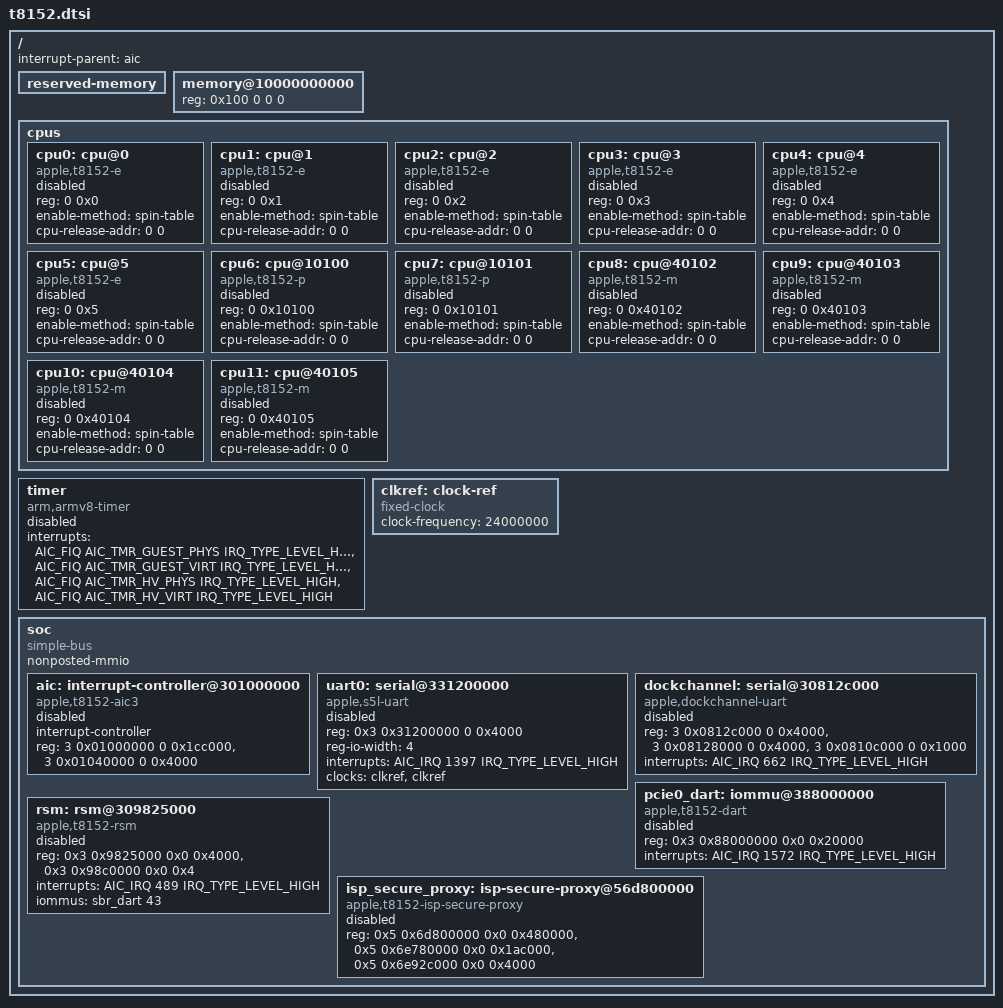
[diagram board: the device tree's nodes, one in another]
// SPDX-License-Identifier: GPL-2.0+ OR MIT
/*
 * Common hardware inventory for boards without a qualified boot profile.
 * Firmware fills RAM and CPU release addresses. Keep new devices disabled;
 * CPU harvesting, firmware handoff and enables need separate qualification.
 */
#include <dt-bindings/interrupt-controller/apple-aic.h>
#include <dt-bindings/interrupt-controller/irq.h>

/ {
	#address-cells = <2>;
	#size-cells = <2>;
	interrupt-parent = <&aic>;

	reserved-memory {
		#address-cells = <2>;
		#size-cells = <2>;
		ranges;
	};

	memory@10000000000 {
		device_type = "memory";
		reg = <0x100 0 0 0>; /* Filled by the loader. */
	};

	cpus {
		#address-cells = <2>;
		#size-cells = <0>;

		cpu0: cpu@0 {
			status = "disabled";
			compatible = "apple,t8152-e";
			device_type = "cpu";
			reg = <0 0x0>;
			enable-method = "spin-table";
			cpu-release-addr = <0 0>; /* Filled by the loader. */
		};

		cpu1: cpu@1 {
			status = "disabled";
			compatible = "apple,t8152-e";
			device_type = "cpu";
			reg = <0 0x1>;
			enable-method = "spin-table";
			cpu-release-addr = <0 0>; /* Filled by the loader. */
		};

		cpu2: cpu@2 {
			status = "disabled";
			compatible = "apple,t8152-e";
			device_type = "cpu";
			reg = <0 0x2>;
			enable-method = "spin-table";
			cpu-release-addr = <0 0>; /* Filled by the loader. */
		};

		cpu3: cpu@3 {
			status = "disabled";
			compatible = "apple,t8152-e";
			device_type = "cpu";
			reg = <0 0x3>;
			enable-method = "spin-table";
			cpu-release-addr = <0 0>; /* Filled by the loader. */
		};

		cpu4: cpu@4 {
			status = "disabled";
			compatible = "apple,t8152-e";
			device_type = "cpu";
			reg = <0 0x4>;
			enable-method = "spin-table";
			cpu-release-addr = <0 0>; /* Filled by the loader. */
		};

		cpu5: cpu@5 {
			status = "disabled";
			compatible = "apple,t8152-e";
			device_type = "cpu";
			reg = <0 0x5>;
			enable-method = "spin-table";
			cpu-release-addr = <0 0>; /* Filled by the loader. */
		};

		cpu6: cpu@10100 {
			status = "disabled";
			compatible = "apple,t8152-p";
			device_type = "cpu";
			reg = <0 0x10100>;
			enable-method = "spin-table";
			cpu-release-addr = <0 0>; /* Filled by the loader. */
		};

		cpu7: cpu@10101 {
			status = "disabled";
			compatible = "apple,t8152-p";
			device_type = "cpu";
			reg = <0 0x10101>;
			enable-method = "spin-table";
			cpu-release-addr = <0 0>; /* Filled by the loader. */
		};

		cpu8: cpu@40102 {
			status = "disabled";
			compatible = "apple,t8152-m";
			device_type = "cpu";
			reg = <0 0x40102>;
			enable-method = "spin-table";
			cpu-release-addr = <0 0>; /* Filled by the loader. */
		};

		cpu9: cpu@40103 {
			status = "disabled";
			compatible = "apple,t8152-m";
			device_type = "cpu";
			reg = <0 0x40103>;
			enable-method = "spin-table";
			cpu-release-addr = <0 0>; /* Filled by the loader. */
		};

		cpu10: cpu@40104 {
			status = "disabled";
			compatible = "apple,t8152-m";
			device_type = "cpu";
			reg = <0 0x40104>;
			enable-method = "spin-table";
			cpu-release-addr = <0 0>; /* Filled by the loader. */
		};

		cpu11: cpu@40105 {
			status = "disabled";
			compatible = "apple,t8152-m";
			device_type = "cpu";
			reg = <0 0x40105>;
			enable-method = "spin-table";
			cpu-release-addr = <0 0>; /* Filled by the loader. */
		};
	};

	timer {
		status = "disabled";
		compatible = "arm,armv8-timer";
		interrupts = <AIC_FIQ AIC_TMR_GUEST_PHYS IRQ_TYPE_LEVEL_HIGH>,
			     <AIC_FIQ AIC_TMR_GUEST_VIRT IRQ_TYPE_LEVEL_HIGH>,
			     <AIC_FIQ AIC_TMR_HV_PHYS IRQ_TYPE_LEVEL_HIGH>,
			     <AIC_FIQ AIC_TMR_HV_VIRT IRQ_TYPE_LEVEL_HIGH>;
		interrupt-names = "phys", "virt", "hyp-phys", "hyp-virt";
	};

	clkref: clock-ref {
		compatible = "fixed-clock";
		#clock-cells = <0>;
		clock-frequency = <24000000>;
	};

	soc {
		compatible = "simple-bus";
		#address-cells = <2>;
		#size-cells = <2>;
		ranges;
		nonposted-mmio;

		aic: interrupt-controller@301000000 {
			status = "disabled";
			compatible = "apple,t8152-aic3", "apple,t8122-aic3";
			interrupt-controller;
			#interrupt-cells = <3>;
			reg = <3 0x01000000 0 0x1cc000>,
			      <3 0x01040000 0 0x4000>;
			reg-names = "core", "event";
		};

	uart0: serial@331200000 {
		status = "disabled";
		compatible = "apple,s5l-uart";
		reg = <0x3 0x31200000 0 0x4000>;
		reg-io-width = <4>;
		interrupts = <AIC_IRQ 1397 IRQ_TYPE_LEVEL_HIGH>;
		clocks = <&clkref>, <&clkref>;
		clock-names = "uart", "clk_uart_baud0";
	};

		dockchannel: serial@30812c000 {
			status = "disabled";
			compatible = "apple,dockchannel-uart";
			reg = <3 0x0812c000 0 0x4000>,
			      <3 0x08128000 0 0x4000>,
			      <3 0x0810c000 0 0x1000>;
			reg-names = "data", "config", "irq";
			interrupts = <AIC_IRQ 662 IRQ_TYPE_LEVEL_HIGH>;
		};
	};
};

/* Native interfaces shared by the hardware-only board descriptions. */
&{/soc} {
	pcie0_dart: iommu@388000000 {
		compatible = "apple,t8152-dart", "apple,t8110-dart";
		reg = <0x3 0x88000000 0x0 0x20000>;
		interrupts = <AIC_IRQ 1572 IRQ_TYPE_LEVEL_HIGH>;
		#iommu-cells = <1>;
		status = "disabled";
	};

	rsm: rsm@309825000 {
		compatible = "apple,t8152-rsm", "apple,rsm";
		reg = <0x3 0x9825000 0x0 0x4000>,
		      <0x3 0x98c0000 0x0 0x4>;
		interrupts = <AIC_IRQ 489 IRQ_TYPE_LEVEL_HIGH>;
		iommus = <&sbr_dart 43>;
		status = "disabled";
	};

	isp_secure_proxy: isp-secure-proxy@56d800000 {
		compatible = "apple,t8152-isp-secure-proxy", "apple,isp-secure-proxy";
		reg = <0x5 0x6d800000 0x0 0x480000>,
		      <0x5 0x6e780000 0x0 0x1ac000>,
		      <0x5 0x6e92c000 0x0 0x4000>;
		status = "disabled";
	};
};

#include "t8152-peripherals.dtsi"
